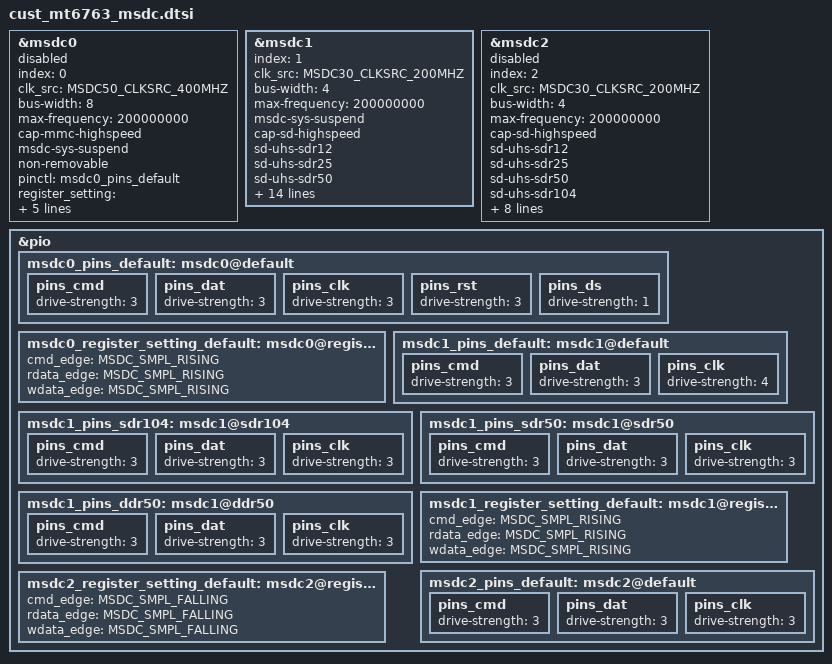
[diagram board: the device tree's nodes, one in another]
/**********************************************
 *MT6757 MSDC DTSI File
********************************************/

&msdc0 {
	index = /bits/ 8 <0>;
	clk_src = /bits/ 8 <MSDC50_CLKSRC_400MHZ>;
	bus-width = <8>;
	max-frequency = <200000000>;
	cap-mmc-highspeed;
	msdc-sys-suspend;
	/*mmc-ddr-1_8v;*/
	/*mmc-hs200-1_8v;*/
	/*mmc-hs400-1_8v;*/
	non-removable;
	pinctl = <&msdc0_pins_default>;
	register_setting = <&msdc0_register_setting_default>;
	host_function = /bits/ 8 <MSDC_EMMC>;
	bootable;
	status = "disable";
	vmmc-supply = <&mt_pmic_vemc_ldo_reg>;
	/*clocks = <&pericfg CLK_PERICFG_RG_MSDC0_AP_NORM>, <&topckgen CLK_TOP_MSDC50_HCLK_SEL>;*/
	/*clock-names = "msdc0-clock", "msdc0-hclock";*/
	hw_dvfs = /bits/ 8 <1>;
};

&msdc1 {
	index = /bits/ 8 <1>;
	clk_src = /bits/ 8 <MSDC30_CLKSRC_200MHZ>;
	bus-width = <4>;
	max-frequency = <200000000>;
	msdc-sys-suspend;
	cap-sd-highspeed;
	sd-uhs-sdr12;
	sd-uhs-sdr25;
	sd-uhs-sdr50;
	sd-uhs-sdr104;
	sd-uhs-ddr50;
	pinctl = <&msdc1_pins_default>;
	pinctl_sdr104 = <&msdc1_pins_sdr104>;
	pinctl_sdr50 = <&msdc1_pins_sdr50>;
	pinctl_ddr50 = <&msdc1_pins_ddr50>;
	register_setting = <&msdc1_register_setting_default>;
	host_function = /bits/ 8 <MSDC_SD>;
	cd_level = /bits/ 8 <MSDC_CD_LOW>;
	cd-gpios = <&pio 3 0>;
	status = "okay";
	vmmc-supply = <&mt_pmic_vmch_ldo_reg>;
	vqmmc-supply = <&mt_pmic_vmc_ldo_reg>;
	/*clocks = <&pericfg CLK_PERICFG_RG_MSDC1>;*/
	/*clock-names = "msdc1-clock";*/
	hw_dvfs = /bits/ 8 <0>;
};

&msdc2 {
	index = /bits/ 8 <2>;
	clk_src = /bits/ 8 <MSDC30_CLKSRC_200MHZ>;
	bus-width = <4>;
	max-frequency = <200000000>;
	cap-sd-highspeed;
	sd-uhs-sdr12;
	sd-uhs-sdr25;
	sd-uhs-sdr50;
	sd-uhs-sdr104;
	sd-uhs-ddr50;
	keep-power-in-suspend;
	non-removable;
	pinctl = <&msdc2_pins_default>;
	register_setting = <&msdc2_register_setting_default>;
	host_function = /bits/ 8 <MSDC_SDIO>;
	status = "disable";
	/*clocks = <&pericfg CLK_PERICFG_RG_MSDC3>, <&topckgen CLK_TOP_MSDC53_HCLK_SEL>;*/
	/*clock-names = "msdc3-clock", "msdc3-hclock";*/
	hw_dvfs = /bits/ 8 <1>;
};

&pio {
	msdc0_pins_default: msdc0@default {
		pins_cmd {
			drive-strength = /bits/ 8 <3>;
		};
		pins_dat {
			drive-strength = /bits/ 8 <3>;
		};
		pins_clk {
			drive-strength = /bits/ 8 <3>;
		};
		pins_rst {
			drive-strength = /bits/ 8 <3>;
		};
		pins_ds {
			drive-strength = /bits/ 8 <1>;
		};
	};

	msdc0_register_setting_default: msdc0@register_default {
		cmd_edge = /bits/ 8 <MSDC_SMPL_RISING>;
		rdata_edge = /bits/ 8 <MSDC_SMPL_RISING>;
		wdata_edge = /bits/ 8 <MSDC_SMPL_RISING>;
	};

	msdc1_pins_default: msdc1@default {
		pins_cmd {
			drive-strength = /bits/ 8 <3>;
		};
		pins_dat {
			drive-strength = /bits/ 8 <3>;
		};
		pins_clk {
			drive-strength = /bits/ 8 <4>;
		};
	};

	msdc1_pins_sdr104: msdc1@sdr104 {
		pins_cmd {
			drive-strength = /bits/ 8 <3>;
		};
		pins_dat {
			drive-strength = /bits/ 8 <3>;
		};
		pins_clk {
			drive-strength = /bits/ 8 <3>;
		};
	};

	msdc1_pins_sdr50: msdc1@sdr50 {
		pins_cmd {
			drive-strength = /bits/ 8 <3>;
		};
		pins_dat {
			drive-strength = /bits/ 8 <3>;
		};
		pins_clk {
			drive-strength = /bits/ 8 <3>;
		};
	};

	msdc1_pins_ddr50: msdc1@ddr50 {
		pins_cmd {
			drive-strength = /bits/ 8 <3>;
		};
		pins_dat {
			drive-strength = /bits/ 8 <3>;
		};
		pins_clk {
			drive-strength = /bits/ 8 <3>;
		};
	};

	msdc1_register_setting_default: msdc1@register_default {
		cmd_edge = /bits/ 8 <MSDC_SMPL_RISING>;
		rdata_edge = /bits/ 8 <MSDC_SMPL_RISING>;
		wdata_edge = /bits/ 8 <MSDC_SMPL_RISING>;
	};

	msdc2_pins_default: msdc2@default {
		pins_cmd {
			drive-strength = /bits/ 8 <3>;
		};
		pins_dat {
			drive-strength = /bits/ 8 <3>;
		};
		pins_clk {
			drive-strength = /bits/ 8 <3>;
		};
	};

	msdc2_register_setting_default: msdc2@register_default {
		cmd_edge = /bits/ 8 <MSDC_SMPL_FALLING>;
		rdata_edge = /bits/ 8 <MSDC_SMPL_FALLING>;
		wdata_edge = /bits/ 8 <MSDC_SMPL_FALLING>;
	};
};

